# STM32F070xB register map
File version: 1.0
Registers are 32-bit, read-write, reset 0x0 unless marked. A register's access mark holds for its fields unless they carry their own. Offsets are from the block's base; [hi:lo] are bit positions; {n}, {i} and the like mark numbered series.

## USB — Universal Serial Bus Full Speed Device
Base 0x40005C00
{0x0+4i} EP{i}R 16-bit (i=0..7) — USB Endpoint {i} register
0x40 CNTR 16-bit — Control register
0x44 ISTR 16-bit — Interrupt status register
0x48 FNR 16-bit — Frame number register
0x4C DADDR 16-bit — Device address register
0x50 BTABLE 16-bit — Buffer Table address register
0x54 LPMCSR 16-bit — LPM Control and Status register
0x58 BCDR 16-bit — Battery Charging detector register

## PWR — Power Control
Base 0x40007000
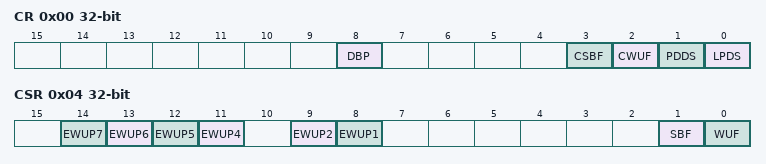
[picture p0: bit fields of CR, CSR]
0x00 CR — PWR power control register
  [8] DBP — Disable Backup Domain write protection
  [3] CSBF — Clear Standby Flag
  [2] CWUF — Clear Wakeup Flag
  [1] PDDS — Power Down Deepsleep
  [0] LPDS — Low-power Deepsleep
    0=MAIN (Voltage Regulator in main mode during deepsleep mode); 1=LOW_POWER (Voltage Regulator in low-power mode during deepsleep mode)
0x04 CSR — PWR power control/status register
  [n+7] EWUP{n} (n=4..7) — Enable WKUP pin {n}
  [9] EWUP2 — Enable WKUP pin 2
  [8] EWUP1 — Enable WKUP pin 1
  [1] SBF — Standby Flag
  [0] WUF — Wakeup Flag

## SYSCFG — SysTem Configuration
Base 0x40010000
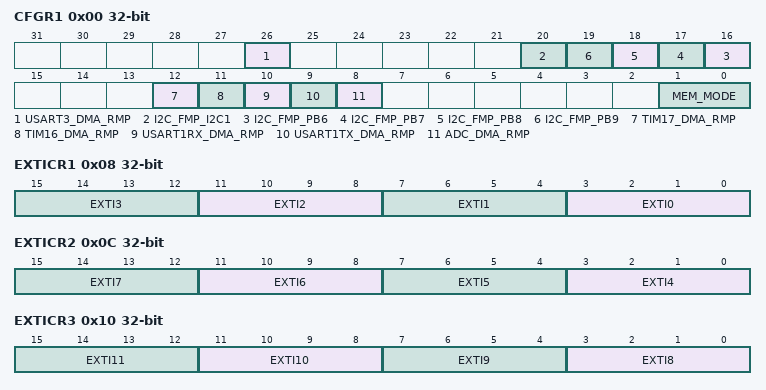
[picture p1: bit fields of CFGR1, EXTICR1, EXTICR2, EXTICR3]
0x00 CFGR1 — SYSCFG configuration register 1
  [26] USART3_DMA_RMP — USART3 DMA remap
  [20] I2C_FMP_I2C1 — Enable Fast Mode Plus on PB10, PB11, PF6 and PF7
  [n+10] I2C_FMP_PB{n} (n=6..9) — I2C PB{n} Fast mode plus
  [12] TIM17_DMA_RMP — Timer 17 DMA remap
  [11] TIM16_DMA_RMP — Timer 16 DMA remap
  [10] USART1RX_DMA_RMP — USART1 RX DMA remap
  [9] USART1TX_DMA_RMP — USART1 TX DMA remap
  [8] ADC_DMA_RMP — ADC DMA remap
    0=CH1 (ADC DMA request mapped on DMA channel 1U); 1=CH2 (ADC DMA request mapped on DMA channel 2U)
  [1:0] MEM_MODE — SYSCFG_Memory Remap Config
    0=FLASH (Main Flash memory mapped at 0x00000000); 1=SYSTEMFLASH (System Flash memory mapped at 0x00000000); 3=SRAM (Embedded SRAM mapped at 0x00000000)
0x08 EXTICR1 — SYSCFG external interrupt configuration register
  [4n+3:4n] EXTI{n} (n=0..3) — EXTI {n} configuration
0x0C EXTICR2 — SYSCFG external interrupt configuration register
  [4n-13:4n-16] EXTI{n} (n=4..7) — EXTI {n} configuration
0x10 EXTICR3 — SYSCFG external interrupt configuration register
  [4n-29:4n-32] EXTI{n} (n=8..11) — EXTI {n} configuration
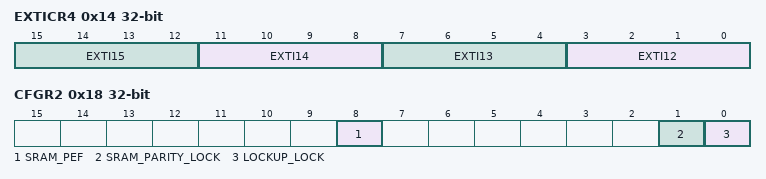
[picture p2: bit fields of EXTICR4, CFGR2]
0x14 EXTICR4 — SYSCFG external interrupt configuration register
  [4n-45:4n-48] EXTI{n} (n=12..15) — EXTI {n} configuration
0x18 CFGR2 — SYSCFG configuration register 2
  [8] SRAM_PEF — SRAM Parity error flag
  [1] SRAM_PARITY_LOCK — Enables and locks the SRAM_PARITY error signal with Break Input of TIMER1
  [0] LOCKUP_LOCK — Enables and locks the LOCKUP (Hardfault) output of CortexM0 with Break Input of TIMER1

## EXTI — External Interrupt/Event Controller
Base 0x40010400
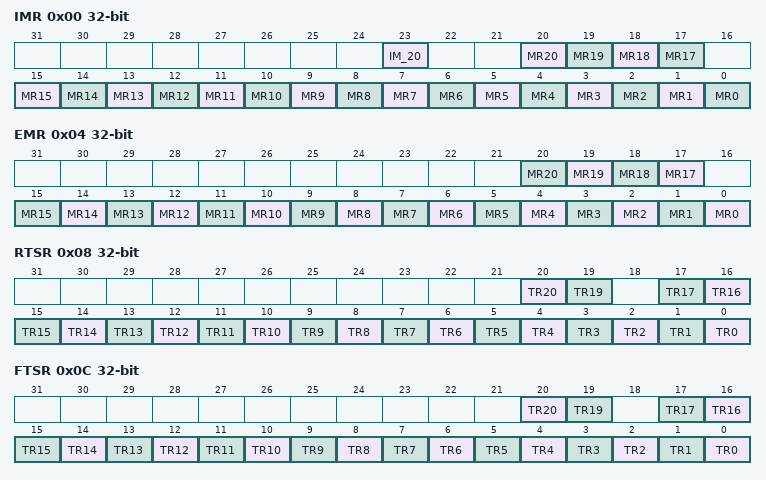
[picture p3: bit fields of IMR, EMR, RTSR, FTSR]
0x00 IMR — EXTI Interrupt mask register
  [23] IM_20 — Interrupt Mask All
  [n] MR{n} (n=17..20) — Interrupt Mask on line {n}
  [n] MR{n} (n=0..15) — Interrupt Mask on line {n}
0x04 EMR — EXTI Event mask register
  [n] MR{n} (n=17..20) — Event Mask on line {n}
  [n] MR{n} (n=0..15) — Event Mask on line {n}
0x08 RTSR — EXTI Rising trigger selection register
  [20] TR20 — Rising trigger event configuration bit of line 20
  [19] TR19 — Rising trigger event configuration bit of line 19
  [n] TR{n} (n=0..17) — Rising trigger event configuration bit of line {n}
0x0C FTSR — EXTI Falling trigger selection register
  [20] TR20 — Falling trigger event configuration bit of line 20
  [19] TR19 — Falling trigger event configuration bit of line 19
  [n] TR{n} (n=0..17) — Falling trigger event configuration bit of line {n}
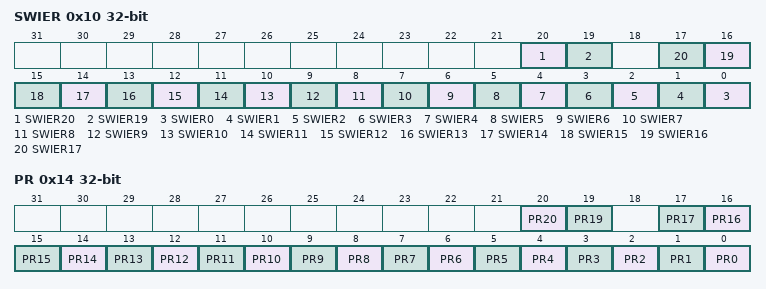
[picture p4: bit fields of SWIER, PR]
0x10 SWIER — EXTI Software interrupt event register
  [20] SWIER20 — Software Interrupt on line 20
  [19] SWIER19 — Software Interrupt on line 19
  [n] SWIER{n} (n=0..17) — Software Interrupt on line {n}
0x14 PR — EXTI Pending register
  [20] PR20 — Pending bit 20
  [19] PR19 — Pending bit 19
  [n] PR{n} (n=0..17) — Pending bit {n}
